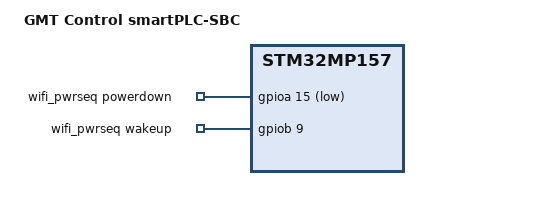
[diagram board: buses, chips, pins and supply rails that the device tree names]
/* SPDX-License-Identifier: (GPL-2.0+ OR BSD-3-Clause) */
/*
 * Copyright (C) STMicroelectronics 2020 - All Rights Reserved
 * Author: STM32CubeMX code generation for STMicroelectronics.
 */

/* For more information on Device Tree configuration, please refer to
 * https://wiki.st.com/stm32mpu/wiki/Category:Device_tree_configuration
 */

/dts-v1/;

#include "stm32mp153.dtsi"
#include "stm32mp15xa.dtsi"
#include "stm32mp15-plc-pinctrl.dtsi"
#include "stm32mp15xxab-pinctrl.dtsi"
#include "stm32mp15-plc.dtsi"

/ {
	model = "GMT Control smartPLC-SBC";
	compatible = "st,stm32mp153a-plc", "st,stm32mp153", "st,stm32mp157";

	aliases {
		serial0 = &usart3;
		serial1 = &usart2;
		ethernet0 = &ethernet0;
		spi0 = &qspi;
	};

	chosen {
		stdout-path = "serial0:115200n8";
	};

	wifi_pwrseq: wifi-pwrseq {
		compatible = "mmc-pwrseq-sd8801";
		power-off-signal-wait-ms = <5>;
		power-on-signal-wait-ms = <50>;
		wake-up-signal-wait-ms = <5>;
		powerdown-gpios = <&gpioa 15 GPIO_ACTIVE_LOW>;
		wakeup-gpios = <&gpiob 9 GPIO_ACTIVE_HIGH>;
	};
};
